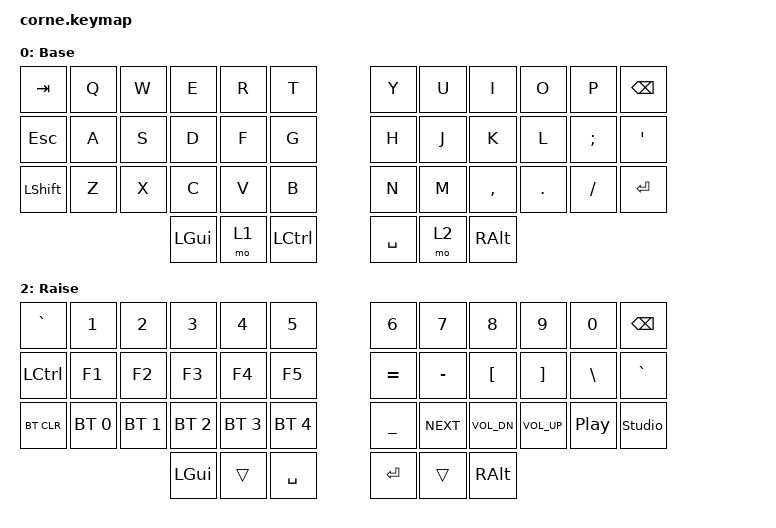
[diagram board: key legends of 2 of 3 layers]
/*
 * Copyright (c) 2020 The ZMK Contributors
 *
 * SPDX-License-Identifier: MIT
 */

#include <behaviors.dtsi>
#include <dt-bindings/zmk/keys.h>
#include <dt-bindings/zmk/bt.h>

/ {
        keymap {
                compatible = "zmk,keymap";

                default_layer {
// -----------------------------------------------------------------------------------------
// |  TAB |  Q  |  W  |  E  |  R  |  T  |   |  Y  |  U   |  I  |  O  |  P  | BKSP |
// | ES C |  A  |  S  |  D  |  F  |  G  |   |  H  |  J   |  K  |  L  |  ;  |  '   |
// | SHFT |  Z  |  X  |  C  |  V  |  B  |   |  N  |  M   |  ,  |  .  |  /  | RET  |
//                    | GUI | LWR | LCTRL |   | SPC | RSE  | ALT |
                        display-name = "Base";
                        bindings = <
   &kp TAB   &kp Q &kp W &kp E &kp R &kp T   &kp Y &kp U  &kp I     &kp O   &kp P    &kp BSPC
   &kp ESC &kp A &kp S &kp D &kp F &kp G   &kp H &kp J  &kp K     &kp L   &kp SEMI &kp SQT
   &kp LSHFT &kp Z &kp X &kp C &kp V &kp B   &kp N &kp M  &kp COMMA &kp DOT &kp FSLH &kp RET
                &kp LGUI &mo 1 &kp LCTRL   &kp SPACE &mo 2 &kp RALT
                        >;
                };
                lower_layer {
// -----------------------------------------------------------------------------------------
// |  ~   |  !  |  @  |  #  |  $  |  %  |   |  ^  |  &  |  *  |  (  |  )  | BKSP |
// | CTRL |  F1 |  F2 |  F3 |  F4 |  F5 |   | LFT | DWN |  UP | RGT |  F6 |      |
// | SHFT |  F7 |  F8 |  F9 | F10 | F11 |   | F12 |   +  |  {  |  } | "|" |  ~   |
//                    | GUI |     | SPC |   | ENT |     | ALT |
                        display-name = "Lower";
                        bindings = <
   &kp TILDE &kp EXCL &kp AT &kp HASH &kp DLLR &kp PRCNT   &kp CARET &kp AMPS  &kp KP_MULTIPLY &kp LPAR &kp RPAR &kp BSPC
   &kp LCTRL &kp F1  &kp F2 &kp F3 &kp F4 &kp F5      &kp LEFT &kp DOWN &kp UP &kp RIGHT &kp F6 &kp &trans
   &kp LSHFT  &kp F7 &kp F8 &kp F9 &kp F10 &kp F11      &kp F12 &kp PLUS  &kp LBRC &kp RBRC &kp PIPE &kp TILDE
        &kp LGUI     &trans       &kp SPACE      &kp RET  &trans   &kp RALT
                        >;
                };

                raise_layer {
// -----------------------------------------------------------------------------------------
// |  `   |  1  |  2  |  3  |  4  |  5  |   |  6  |  7  |  8  |  9  |  0  | BKSP |
// | CTRL |  F1 |  F2 |  F3 |  F4 |  F5 |   |  =  |  -  |  [  |  ]  |  \  |  `   |
// | BCLR | BT1 | BT2 | BT3 | BT4 | BT5 |   |  _  | C_SKIP | C_VOL_DN | C_VOL_UP | PP | UNLOCK |

//                    | GUI |     | SPC |   | ENT |     | ALT |
                        display-name = "Raise";
                        bindings = <
   &kp GRAVE &kp N1 &kp N2 &kp N3 &kp N4 &kp N5   &kp N6 &kp N7 &kp N8 &kp N9 &kp N0 &kp BSPC
   &kp LCTRL &kp F1   &kp F2 &kp F3   &kp F4   &kp F5      &kp EQUAL &kp MINUS &kp LBKT        &kp RBKT &kp BSLH &kp GRAVE
   &bt BT_CLR &bt BT_SEL 0   &bt BT_SEL  1 &bt BT_SEL 2   &bt BT_SEL 3   &bt BT_SEL 4      &kp UNDER &kp C_NEXT &kp C_VOL_DN &kp C_VOL_UP &kp C_PP &studio_unlock
        &kp LGUI &trans   &kp SPACE   &kp RET   &trans    &kp RALT
                        >;
                };
        };
};
